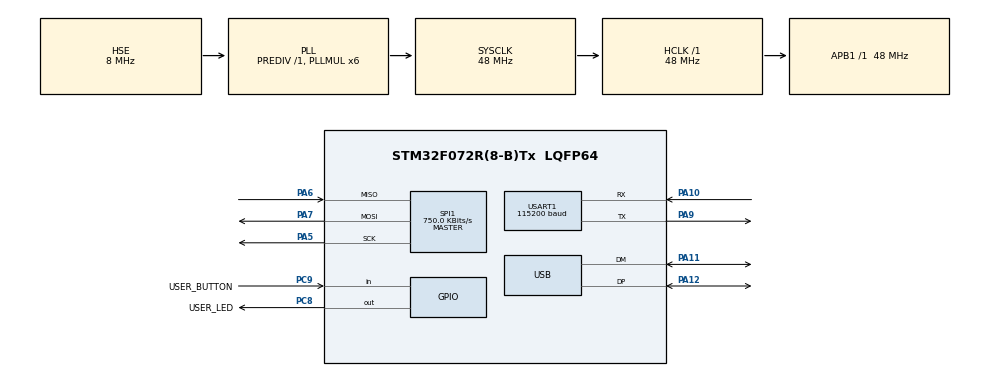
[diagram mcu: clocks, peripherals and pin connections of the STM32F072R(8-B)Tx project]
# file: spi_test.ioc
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Mcu.Family=STM32F0
Mcu.Name=STM32F072R(8-B)Tx
Mcu.Package=LQFP64
PA10.Mode=Asynchronous
PA10.Signal=USART1_RX
PA11.Mode=Device
PA11.Signal=USB_DM
PA12.Mode=Device
PA12.Signal=USB_DP
PA13.Mode=Serial_Wire
PA13.Signal=SYS_SWDIO
PA14.Mode=Serial_Wire
PA14.Signal=SYS_SWCLK
PA5.Mode=Full_Duplex_Master
PA5.Signal=SPI1_SCK
PA6.Mode=Full_Duplex_Master
PA6.Signal=SPI1_MISO
PA7.Mode=Full_Duplex_Master
PA7.Signal=SPI1_MOSI
PA9.Mode=Asynchronous
PA9.Signal=USART1_TX
PC8.GPIO_Label=USER_LED
PC8.PinState=GPIO_PIN_SET
PC8.Signal=GPIO_Output
PC9.GPIO_Label=USER_BUTTON
PC9.GPIO_PuPd=GPIO_PULLUP
PC9.Signal=GPIO_Input
PF0-OSC_IN.Mode=HSE-External-Oscillator
PF0-OSC_IN.Signal=RCC_OSC_IN
PF1-OSC_OUT.Mode=HSE-External-Oscillator
PF1-OSC_OUT.Signal=RCC_OSC_OUT
ProjectManager.HeapSize=0x200
ProjectManager.StackSize=0x400
ProjectManager.TargetToolchain=MDK-ARM V5
RCC.AHBFreq_Value=48000000
RCC.APB1Freq_Value=48000000
RCC.APB1TimFreq_Value=48000000
RCC.HCLKFreq_Value=48000000
RCC.PLLMUL=RCC_PLL_MUL6
RCC.SYSCLKFreq_VALUE=48000000
RCC.SYSCLKSource=RCC_SYSCLKSOURCE_PLLCLK
RCC.USBClockSelection=RCC_USBCLKSOURCE_PLL
RCC.USBFreq_Value=48000000
RCC.Usart1ClockSelection=RCC_USART1CLKSOURCE_SYSCLK
SPI1.BaudRatePrescaler=SPI_BAUDRATEPRESCALER_64
SPI1.CalculateBaudRate=750.0 KBits/s
SPI1.DataSize=SPI_DATASIZE_8BIT
SPI1.Direction=SPI_DIRECTION_2LINES
SPI1.Mode=SPI_MODE_MASTER
SPI1.VirtualType=VM_MASTER
USART1.BaudRate=115200
USART1.VirtualMode-Asynchronous=VM_ASYNC
USART1.WordLength=WORDLENGTH_8B
board=spi_test

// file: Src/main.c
/**
  ******************************************************************************
  * File Name          : main.c
  * Description        : Main program body
  ******************************************************************************
  *
  * COPYRIGHT(c) 2017 STMicroelectronics
  *
  * Redistribution and use in source and binary forms, with or without modification,
  * are permitted provided that the following conditions are met:
  *   1. Redistributions of source code must retain the above copyright notice,
  *      this list of conditions and the following disclaimer.
  *   2. Redistributions in binary form must reproduce the above copyright notice,
  *      this list of conditions and the following disclaimer in the documentation
  *      and/or other materials provided with the distribution.
  *   3. Neither the name of STMicroelectronics nor the names of its contributors
  *      may be used to endorse or promote products derived from this software
  *      without specific prior written permission.
  *
  * THIS SOFTWARE IS PROVIDED BY THE COPYRIGHT HOLDERS AND CONTRIBUTORS "AS IS"
  * AND ANY EXPRESS OR IMPLIED WARRANTIES, INCLUDING, BUT NOT LIMITED TO, THE
  * IMPLIED WARRANTIES OF MERCHANTABILITY AND FITNESS FOR A PARTICULAR PURPOSE ARE
  * DISCLAIMED. IN NO EVENT SHALL THE COPYRIGHT HOLDER OR CONTRIBUTORS BE LIABLE
  * FOR ANY DIRECT, INDIRECT, INCIDENTAL, SPECIAL, EXEMPLARY, OR CONSEQUENTIAL
  * DAMAGES (INCLUDING, BUT NOT LIMITED TO, PROCUREMENT OF SUBSTITUTE GOODS OR
  * SERVICES; LOSS OF USE, DATA, OR PROFITS; OR BUSINESS INTERRUPTION) HOWEVER
  * CAUSED AND ON ANY THEORY OF LIABILITY, WHETHER IN CONTRACT, STRICT LIABILITY,
  * OR TORT (INCLUDING NEGLIGENCE OR OTHERWISE) ARISING IN ANY WAY OUT OF THE USE
  * OF THIS SOFTWARE, EVEN IF ADVISED OF THE POSSIBILITY OF SUCH DAMAGE.
  *
  ******************************************************************************
  */
#include "main.h"
#include "stm32f0xx_hal.h"

SPI_HandleTypeDef hspi1;

UART_HandleTypeDef huart1;

PCD_HandleTypeDef hpcd_USB_FS;

/* USER CODE BEGIN PV */
/* Private variables ---------------------------------------------------------*/

/* USER CODE END PV */

void SystemClock_Config(void);
void Error_Handler(void);
static void MX_GPIO_Init(void);
static void MX_USART1_UART_Init(void);
static void MX_USB_PCD_Init(void);
static void MX_SPI1_Init(void);

/* USER CODE BEGIN PFP */
/* Private function prototypes -----------------------------------------------*/

/* USER CODE END PFP */

int main(void)
{

  /* MCU Configuration----------------------------------------------------------*/

  /* Reset of all peripherals, Initializes the Flash interface and the Systick. */
  HAL_Init();

  /* Configure the system clock */
  SystemClock_Config();

  /* Initialize all configured peripherals */
  MX_GPIO_Init();
  MX_USART1_UART_Init();
  MX_USB_PCD_Init();
  MX_SPI1_Init();

  /* Infinite loop */
  while (1)
  {

  /* USER CODE BEGIN 3 */
  	if(HAL_GPIO_ReadPin(USER_BUTTON_GPIO_Port, USER_BUTTON_Pin) == GPIO_PIN_RESET)
  	{
  		HAL_GPIO_TogglePin(USER_LED_GPIO_Port, USER_LED_Pin);
  		HAL_Delay(500);
  	}
  }
  /* USER CODE END 3 */

}

/** System Clock Configuration
*/
void SystemClock_Config(void)
{

  RCC_OscInitTypeDef RCC_OscInitStruct;
  RCC_ClkInitTypeDef RCC_ClkInitStruct;
  RCC_PeriphCLKInitTypeDef PeriphClkInit;

    /**Initializes the CPU, AHB and APB busses clocks
    */
  RCC_OscInitStruct.OscillatorType = RCC_OSCILLATORTYPE_HSE;
  RCC_OscInitStruct.HSEState = RCC_HSE_ON;
  RCC_OscInitStruct.HSIState = RCC_HSI_ON;
  RCC_OscInitStruct.PLL.PLLState = RCC_PLL_ON;
  RCC_OscInitStruct.PLL.PLLSource = RCC_PLLSOURCE_HSE;
  RCC_OscInitStruct.PLL.PLLMUL = RCC_PLL_MUL6;
  RCC_OscInitStruct.PLL.PREDIV = RCC_PREDIV_DIV1;
  if (HAL_RCC_OscConfig(&RCC_OscInitStruct) != HAL_OK)
  {
    Error_Handler();
  }

    /**Initializes the CPU, AHB and APB busses clocks
    */
  RCC_ClkInitStruct.ClockType = RCC_CLOCKTYPE_HCLK|RCC_CLOCKTYPE_SYSCLK
                              |RCC_CLOCKTYPE_PCLK1;
  RCC_ClkInitStruct.SYSCLKSource = RCC_SYSCLKSOURCE_PLLCLK;
  RCC_ClkInitStruct.AHBCLKDivider = RCC_SYSCLK_DIV1;
  RCC_ClkInitStruct.APB1CLKDivider = RCC_HCLK_DIV1;

  if (HAL_RCC_ClockConfig(&RCC_ClkInitStruct, FLASH_LATENCY_1) != HAL_OK)
  {
    Error_Handler();
  }

  PeriphClkInit.PeriphClockSelection = RCC_PERIPHCLK_USB|RCC_PERIPHCLK_USART1;
  PeriphClkInit.Usart1ClockSelection = RCC_USART1CLKSOURCE_SYSCLK;
  PeriphClkInit.UsbClockSelection = RCC_USBCLKSOURCE_PLL;

  if (HAL_RCCEx_PeriphCLKConfig(&PeriphClkInit) != HAL_OK)
  {
    Error_Handler();
  }

    /**Configure the Systick interrupt time
    */
  HAL_SYSTICK_Config(HAL_RCC_GetHCLKFreq()/1000);

    /**Configure the Systick
    */
  HAL_SYSTICK_CLKSourceConfig(SYSTICK_CLKSOURCE_HCLK);

  /* SysTick_IRQn interrupt configuration */
  HAL_NVIC_SetPriority(SysTick_IRQn, 0, 0);
}

/* SPI1 init function */
static void MX_SPI1_Init(void)
{

  hspi1.Instance = SPI1;
  hspi1.Init.Mode = SPI_MODE_MASTER;
  hspi1.Init.Direction = SPI_DIRECTION_2LINES;
  hspi1.Init.DataSize = SPI_DATASIZE_8BIT;
  hspi1.Init.CLKPolarity = SPI_POLARITY_LOW;
  hspi1.Init.CLKPhase = SPI_PHASE_1EDGE;
  hspi1.Init.NSS = SPI_NSS_SOFT;
  hspi1.Init.BaudRatePrescaler = SPI_BAUDRATEPRESCALER_64;
  hspi1.Init.FirstBit = SPI_FIRSTBIT_MSB;
  hspi1.Init.TIMode = SPI_TIMODE_DISABLE;
  hspi1.Init.CRCCalculation = SPI_CRCCALCULATION_DISABLE;
  hspi1.Init.CRCPolynomial = 7;
  hspi1.Init.CRCLength = SPI_CRC_LENGTH_DATASIZE;
  hspi1.Init.NSSPMode = SPI_NSS_PULSE_ENABLE;
  if (HAL_SPI_Init(&hspi1) != HAL_OK)
  {
    Error_Handler();
  }

}

/* USART1 init function */
static void MX_USART1_UART_Init(void)
{

  huart1.Instance = USART1;
  huart1.Init.BaudRate = 115200;
  huart1.Init.WordLength = UART_WORDLENGTH_8B;
  huart1.Init.StopBits = UART_STOPBITS_1;
  huart1.Init.Parity = UART_PARITY_NONE;
  huart1.Init.Mode = UART_MODE_TX_RX;
  huart1.Init.HwFlowCtl = UART_HWCONTROL_NONE;
  huart1.Init.OverSampling = UART_OVERSAMPLING_16;
  huart1.Init.OneBitSampling = UART_ONE_BIT_SAMPLE_DISABLE;
  huart1.AdvancedInit.AdvFeatureInit = UART_ADVFEATURE_NO_INIT;
  if (HAL_UART_Init(&huart1) != HAL_OK)
  {
    Error_Handler();
  }

}

/* USB init function */
static void MX_USB_PCD_Init(void)
{

  hpcd_USB_FS.Instance = USB;
  hpcd_USB_FS.Init.dev_endpoints = 8;
  hpcd_USB_FS.Init.speed = PCD_SPEED_FULL;
  hpcd_USB_FS.Init.ep0_mps = DEP0CTL_MPS_64;
  hpcd_USB_FS.Init.phy_itface = PCD_PHY_EMBEDDED;
  hpcd_USB_FS.Init.low_power_enable = DISABLE;
  hpcd_USB_FS.Init.lpm_enable = DISABLE;
  hpcd_USB_FS.Init.battery_charging_enable = DISABLE;
  if (HAL_PCD_Init(&hpcd_USB_FS) != HAL_OK)
  {
    Error_Handler();
  }

}

/** Configure pins as
        * Analog
        * Input
        * Output
        * EVENT_OUT
        * EXTI
*/
static void MX_GPIO_Init(void)
{

  GPIO_InitTypeDef GPIO_InitStruct;

  /* GPIO Ports Clock Enable */
  __HAL_RCC_GPIOF_CLK_ENABLE();
  __HAL_RCC_GPIOA_CLK_ENABLE();
  __HAL_RCC_GPIOC_CLK_ENABLE();

  /*Configure GPIO pin Output Level */
  HAL_GPIO_WritePin(USER_LED_GPIO_Port, USER_LED_Pin, GPIO_PIN_SET);

  /*Configure GPIO pin : USER_LED_Pin */
  GPIO_InitStruct.Pin = USER_LED_Pin;
  GPIO_InitStruct.Mode = GPIO_MODE_OUTPUT_PP;
  GPIO_InitStruct.Pull = GPIO_NOPULL;
  GPIO_InitStruct.Speed = GPIO_SPEED_FREQ_LOW;
  HAL_GPIO_Init(USER_LED_GPIO_Port, &GPIO_InitStruct);

  /*Configure GPIO pin : USER_BUTTON_Pin */
  GPIO_InitStruct.Pin = USER_BUTTON_Pin;
  GPIO_InitStruct.Mode = GPIO_MODE_INPUT;
  GPIO_InitStruct.Pull = GPIO_PULLUP;
  HAL_GPIO_Init(USER_BUTTON_GPIO_Port, &GPIO_InitStruct);

}

void Error_Handler(void)
{
  while(1)
  {
  }
}

/************************ (C) COPYRIGHT STMicroelectronics *****END OF FILE****/
